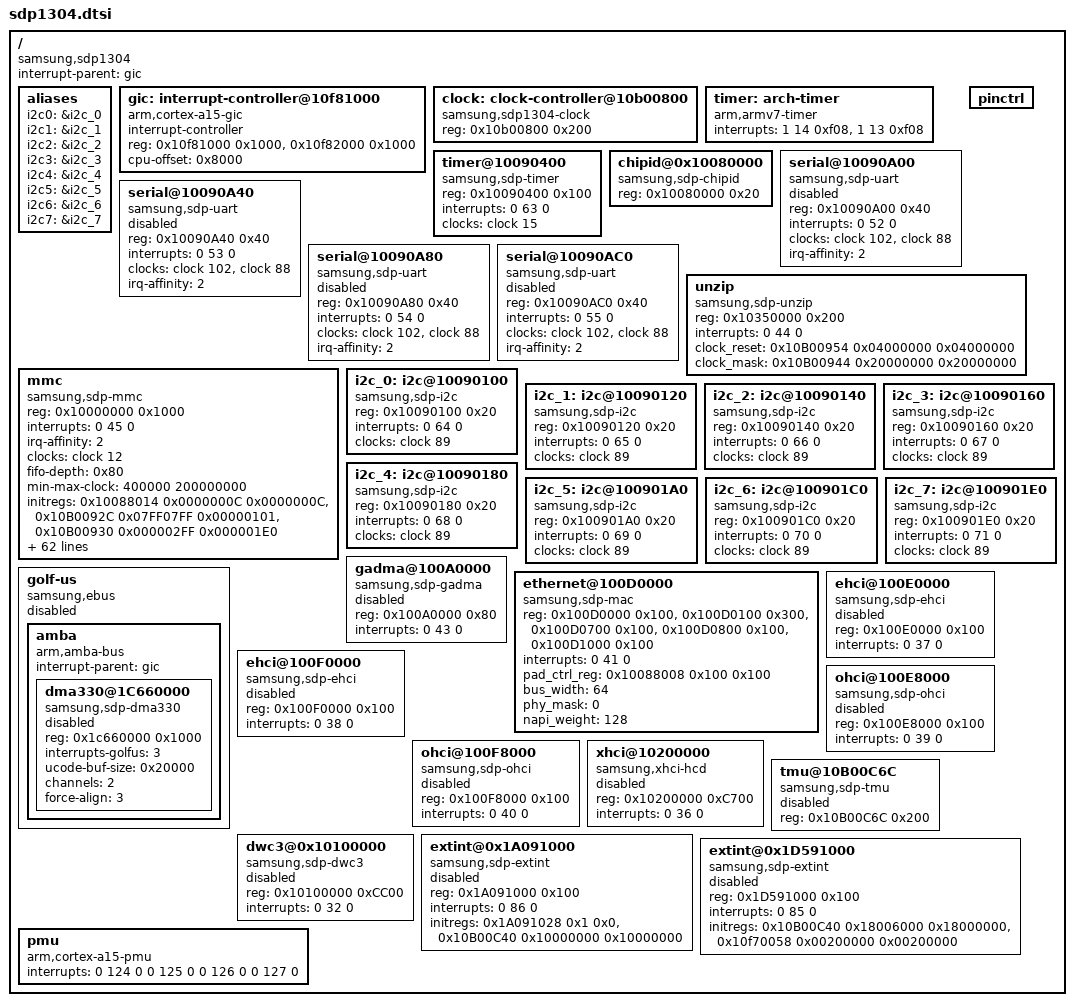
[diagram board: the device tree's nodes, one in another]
/*
 * Copyright (C) 2013 Samsung Electronics Co.Ltd
 *
 * This program is free software; you can redistribute it and/or modify
 * it under the terms of the GNU General Public License version 2 as
 * published by the Free Software Foundation.
 */

/include/ "sdp.dtsi"
/include/ "sdp1304-pinctrl.dtsi"

/ {
	compatible = "samsung,sdp1304";

	interrupt-parent = <&gic>;

	aliases {
		i2c0 = &i2c_0;
		i2c1 = &i2c_1;
		i2c2 = &i2c_2;
		i2c3 = &i2c_3;
		i2c4 = &i2c_4;
		i2c5 = &i2c_5;
		i2c6 = &i2c_6;
		i2c7 = &i2c_7;
	};

	gic: interrupt-controller@10f81000 {
		compatible = "arm,cortex-a15-gic";
		interrupt-controller;
		#interrupt-cells = <3>;
		reg = <0x10f81000 0x1000>, <0x10f82000 0x1000>;
		cpu-offset = <0x8000>;
	};

	clock: clock-controller@10b00800 {
		compatible = "samsung,sdp1304-clock";
		reg = <0x10b00800 0x200>;
		#clock-cells = <1>;
	};

	timer: arch-timer {
		compatible = "arm,armv7-timer";
		interrupts = <1 14 0xf08>,
					 <1 13 0xf08>;
	};

	timer@10090400 {
		compatible = "samsung,sdp-timer";
		reg = <0x10090400 0x100>;
		interrupts = <0 63 0>;
		clocks = <&clock 15>;
		clock-names = "ahb_clk";
	};

	chipid@0x10080000 {
		compatible = "samsung,sdp-chipid";
		reg = <0x10080000 0x20>;
	};

	serial@10090A00 {
		compatible = "samsung,sdp-uart";
		reg = <0x10090A00 0x40>;
		interrupts = <0 52 0>;
		clocks = <&clock 102>, <&clock 88>;
		clock-names = "apb_pclk", "rstn_uart";
		irq-affinity = <2>;
		status = "disabled";
	};

	serial@10090A40 {
		compatible = "samsung,sdp-uart";
		reg = <0x10090A40 0x40>;
		interrupts = <0 53 0>;
		clocks = <&clock 102>, <&clock 88>;
		clock-names = "apb_pclk", "rstn_uart";
		irq-affinity = <2>;
		status = "disabled";
	};

	serial@10090A80 {
		compatible = "samsung,sdp-uart";
		reg = <0x10090A80 0x40>;
		interrupts = <0 54 0>;
		clocks = <&clock 102>, <&clock 88>;
		clock-names = "apb_pclk", "rstn_uart";
		irq-affinity = <2>;
		status = "disabled";
	};

	serial@10090AC0 {
		compatible = "samsung,sdp-uart";
		reg = <0x10090AC0 0x40>;
		interrupts = <0 55 0>;
		clocks = <&clock 102>, <&clock 88>;
		clock-names = "apb_pclk", "rstn_uart";
		irq-affinity = <2>;
		status = "disabled";
	};

	pinctrl{
		status = "okay";
	};

	unzip {
		compatible = "samsung,sdp-unzip";
		reg = <0x10350000 0x200>;
		interrupts = < 0 44 0 >;
		clock_reset = <0x10B00954 0x04000000 0x04000000>; 
		clock_mask = <0x10B00944 0x20000000 0x20000000>;
	};

	mmc {
		compatible = "samsung,sdp-mmc";
		reg = <0x10000000 0x1000>;
		interrupts = <0 45 0>;
		irq-affinity = <2>;
		clocks = <&clock 12>;
		clock-names = "emmc_clk";
		fifo-depth = <0x80>;
		min-max-clock = <400000 200000000>;
		initregs =	<0x10088014 0x0000000C 0x0000000C>,/* 33bit Accesss setting */
					<0x10B0092C 0x07FF07FF 0x00000101>,/* drv bypass, sam 0x101 delay */
					<0x10B00930 0x000002FF 0x000001E0>;/* sam buffer delay max, drv buffer delay min */

//		restoreregs =	<0x10B0092C 0x7FFF7FFF>;

		/* eMMC Sampling Clock Delay Selection. 1.25ns ~ 5ns for HS200 */
		tuning_set_size = <2>;
        tuning_sam =    <0x10B0092C 0x000007FF 0x00000100>, <0x10B00930 0x000001E0 0x00000000>,
                        <0x10B0092C 0x000007FF 0x00000100>, <0x10B00930 0x000001E0 0x000001E0>,
                        <0x10B0092C 0x000007FF 0x00000101>, <0x10B00930 0x000001E0 0x00000000>,
                        <0x10B0092C 0x000007FF 0x00000101>, <0x10B00930 0x000001E0 0x000001E0>,
                        <0x10B0092C 0x000007FF 0x00000102>, <0x10B00930 0x000001E0 0x00000000>,
                        <0x10B0092C 0x000007FF 0x00000102>, <0x10B00930 0x000001E0 0x000001E0>,
                        <0x10B0092C 0x000007FF 0x00000103>, <0x10B00930 0x000001E0 0x00000000>,
                        <0x10B0092C 0x000007FF 0x00000103>, <0x10B00930 0x000001E0 0x000001E0>,
                        <0x10B0092C 0x000007FF 0x00000200>, <0x10B00930 0x000001E0 0x00000000>,
                        <0x10B0092C 0x000007FF 0x00000200>, <0x10B00930 0x000001E0 0x000001E0>,
                        <0x10B0092C 0x000007FF 0x00000204>, <0x10B00930 0x000001E0 0x00000000>,
                        <0x10B0092C 0x000007FF 0x00000204>, <0x10B00930 0x000001E0 0x000001E0>,
                        <0x10B0092C 0x000007FF 0x00000208>, <0x10B00930 0x000001E0 0x00000000>,
                        <0x10B0092C 0x000007FF 0x00000208>, <0x10B00930 0x000001E0 0x000001E0>,
                        <0x10B0092C 0x000007FF 0x0000020C>, <0x10B00930 0x000001E0 0x00000000>,
                        <0x10B0092C 0x000007FF 0x0000020C>, <0x10B00930 0x000001E0 0x000001E0>,
                        <0x10B0092C 0x000007FF 0x00000300>, <0x10B00930 0x000001E0 0x00000000>,
                        <0x10B0092C 0x000007FF 0x00000300>, <0x10B00930 0x000001E0 0x000001E0>,
                        <0x10B0092C 0x000007FF 0x00000310>, <0x10B00930 0x000001E0 0x00000000>,
                        <0x10B0092C 0x000007FF 0x00000310>, <0x10B00930 0x000001E0 0x000001E0>,
                        <0x10B0092C 0x000007FF 0x00000320>, <0x10B00930 0x000001E0 0x00000000>,
                        <0x10B0092C 0x000007FF 0x00000320>, <0x10B00930 0x000001E0 0x000001E0>,
                        <0x10B0092C 0x000007FF 0x00000330>, <0x10B00930 0x000001E0 0x00000000>,
                        <0x10B0092C 0x000007FF 0x00000330>, <0x10B00930 0x000001E0 0x000001E0>;
                        //<0x10B0092C 0x000007FF 0x00000400>, <0x10B00930 0x000001E0 0x00000000>,
                        //<0x10B0092C 0x000007FF 0x00000400>, <0x10B00930 0x000001E0 0x000001E0>,
                        //<0x10B0092C 0x000007FF 0x00000410>, <0x10B00930 0x000001E0 0x00000000>,
                        //<0x10B0092C 0x000007FF 0x00000410>, <0x10B00930 0x000001E0 0x000001E0>,
                        //<0x10B0092C 0x000007FF 0x00000420>, <0x10B00930 0x000001E0 0x00000000>,
                        //<0x10B0092C 0x000007FF 0x00000420>, <0x10B00930 0x000001E0 0x000001E0>,
                        //<0x10B0092C 0x000007FF 0x00000430>, <0x10B00930 0x000001E0 0x00000000>,
                        //<0x10B0092C 0x000007FF 0x00000430>, <0x10B00930 0x000001E0 0x000001E0>;
                        //<0x10B0092C 0x000007FF 0x00000500>, <0x10B00930 0x000001E0 0x00000000>,
                        //<0x10B0092C 0x000007FF 0x00000500>, <0x10B00930 0x000001E0 0x000001E0>,
                        //<0x10B0092C 0x000007FF 0x00000510>, <0x10B00930 0x000001E0 0x00000000>,
                        //<0x10B0092C 0x000007FF 0x00000510>, <0x10B00930 0x000001E0 0x000001E0>,
                        //<0x10B0092C 0x000007FF 0x00000520>, <0x10B00930 0x000001E0 0x00000000>,
                        //<0x10B0092C 0x000007FF 0x00000520>, <0x10B00930 0x000001E0 0x000001E0>,
                        //<0x10B0092C 0x000007FF 0x00000530>, <0x10B00930 0x000001E0 0x00000000>,
                        //<0x10B0092C 0x000007FF 0x00000530>, <0x10B00930 0x000001E0 0x000001E0>;

        tuning_sam_hs200_default = <0x10B0092C 0x000007FF 0x00000100>, <0x10B00930 0x000001E0 0x00000000>;/* HS200 sampling defalut */
        tuning_drv_hs200_default = <0x10B0092C 0x07FF0000 0x02080000>, <0x10B00930 0x0000000F 0x0000000F>, <0x10B00804 0xFFFFFFFF 0x0030FA01>, <0x10B00908 0x0000000F 0x00000005>;/* HS200 driving defalut HS200 166Mhz */

		bus-width = <0x8>;
//		force-pio-mode;
		hw-reset;

		/* Host Caps */
		non-removable;
//		bus-width-test;
		highspeed;
//		sdr104;
		ddr50;
//		hs200;
//		hs200-tuning;
	};

	i2c_0: i2c@10090100 {
		#address-cells = <1>;
		#size-cells = <0>;
		compatible = "samsung,sdp-i2c";
		reg = <0x10090100 0x20>;
		interrupts = <0 64 0>;
		clocks = <&clock 89>;
		clock-names = "rstn_i2c";
	};

	i2c_1: i2c@10090120 {
		#address-cells = <1>;
		#size-cells = <0>;
		compatible = "samsung,sdp-i2c";
		reg = <0x10090120 0x20>;
		interrupts = <0 65 0>;
		clocks = <&clock 89>;
		clock-names = "rstn_i2c";
	};

	i2c_2: i2c@10090140 {
		#address-cells = <1>;
		#size-cells = <0>;
		compatible = "samsung,sdp-i2c";
		reg = <0x10090140 0x20>;
		interrupts = <0 66 0>;
		clocks = <&clock 89>;
		clock-names = "rstn_i2c";
	};

	i2c_3: i2c@10090160 {
		#address-cells = <1>;
		#size-cells = <0>;
		compatible = "samsung,sdp-i2c";
		reg = <0x10090160 0x20>;
		interrupts = <0 67 0>;
		clocks = <&clock 89>;
		clock-names = "rstn_i2c";
	};

	i2c_4: i2c@10090180 {
		#address-cells = <1>;
		#size-cells = <0>;
		compatible = "samsung,sdp-i2c";
		reg = <0x10090180 0x20>;
		interrupts = <0 68 0>;
		clocks = <&clock 89>;
		clock-names = "rstn_i2c";
	};

	i2c_5: i2c@100901A0 {
		#address-cells = <1>;
		#size-cells = <0>;
		compatible = "samsung,sdp-i2c";
		reg = <0x100901A0 0x20>;
		interrupts = <0 69 0>;
		clocks = <&clock 89>;
		clock-names = "rstn_i2c";
	};

	i2c_6: i2c@100901C0 {
		#address-cells = <1>;
		#size-cells = <0>;
		compatible = "samsung,sdp-i2c";
		reg = <0x100901C0 0x20>;
		interrupts = <0 70 0>;
		clocks = <&clock 89>;
		clock-names = "rstn_i2c";
	};

	i2c_7: i2c@100901E0 {
		#address-cells = <1>;
		#size-cells = <0>;
		compatible = "samsung,sdp-i2c";
		reg = <0x100901E0 0x20>;
		interrupts = <0 71 0>;
		clocks = <&clock 89>;
		clock-names = "rstn_i2c";
	};

	gadma@100A0000 {
		compatible = "samsung,sdp-gadma";
		reg = <0x100A0000 0x80>;
		interrupts = <0 43 0>;
		status = "disabled";
	};


	golf-us {
		status = "disabled";

		#address-cells = <1>;
		#size-cells = <1>;
		compatible = "samsung,ebus", "simple-bus";
		ranges;

		amba {
			#address-cells = <1>;
			#size-cells = <1>;
			compatible = "arm,amba-bus";
			interrupt-parent = <&gic>;
			ranges;

			dma330@1C660000 {
				status = "disabled";
				compatible = "samsung,sdp-dma330", "arm,primecell";
				reg = <0x1c660000 0x1000>;
				interrupts-golfus = <3>;

				ucode-buf-size = <0x20000>;/*128kb*/
				channels = <2>;
				force-align = <3>;/* 2^n */
			};
		};
	};

	ethernet@100D0000 {
		compatible = "samsung,sdp-mac";
		reg = <0x100D0000 0x100>,
			<0x100D0100 0x300>,
			<0x100D0700 0x100>,
			<0x100D0800 0x100>,
			<0x100D1000 0x100>;
		interrupts = <0 41 0>;
		pad_ctrl_reg = <0x10088008 0x100 0x100>;
		bus_width = <64>;
		phy_mask = <0>;
		napi_weight = <128>;
	};

	ehci@100E0000 {
		compatible = "samsung,sdp-ehci", "usb-ehci";
		reg = <0x100E0000 0x100>;
		interrupts = <0 37 0>;
		status = "disabled";
	};

	ehci@100F0000 {
		compatible = "samsung,sdp-ehci", "usb-ehci";
		reg = <0x100F0000 0x100>;
		interrupts = <0 38 0>;
		status = "disabled";
	};

	ohci@100E8000 {
		compatible = "samsung,sdp-ohci", "usb-ohci";
		reg = <0x100E8000 0x100>;
		interrupts = <0 39 0>;
		status = "disabled";
	};

	ohci@100F8000 {
		compatible = "samsung,sdp-ohci", "usb-ohci";
		reg = <0x100F8000 0x100>;
		interrupts = <0 40 0>;
		status = "disabled";
	};

	xhci@10200000 {
		compatible = "samsung,xhci-hcd", "usb-xhci";
		reg = <0x10200000 0xC700>;
		interrupts = <0 36 0>;
		status = "disabled";
	};

	tmu@10B00C6C {
		compatible = "samsung,sdp-tmu";
		reg = <0x10B00C6C 0x200>;
		status = "disabled";
	};

	dwc3@0x10100000 {
		compatible = "samsung,sdp-dwc3";
		reg = <0x10100000 0xCC00>;
		interrupts = <0 32 0>;
		status = "disabled";
	};
	
	extint@0x1A091000 {
		compatible = "samsung,sdp-extint";
		reg = <0x1A091000 0x100>;
		interrupts = <0 86 0>;
		initregs = <0x1A091028 0x1 0x0>,	/* STM off */
			<0x10B00C40 0x10000000 0x10000000>;		/* Externel Interrupt Enable */
		status = "disabled";
	};

	extint@0x1D591000 {
		compatible = "samsung,sdp-extint";
		reg = <0x1D591000 0x100>;
		interrupts = <0 85 0>;
		initregs = <0x10B00C40 0x18006000 0x18000000>,	/* Externel Interrupt Enable */
			<0x10f70058 0x00200000 0x00200000>;	/* GIC Polarity Invert */
		status = "disabled";
	};
	
	pmu	{
		compatible = "arm,cortex-a15-pmu";
		interrupts = <0 124 0
				0 125 0
				0 126 0
				0 127 0>;
	};
};
